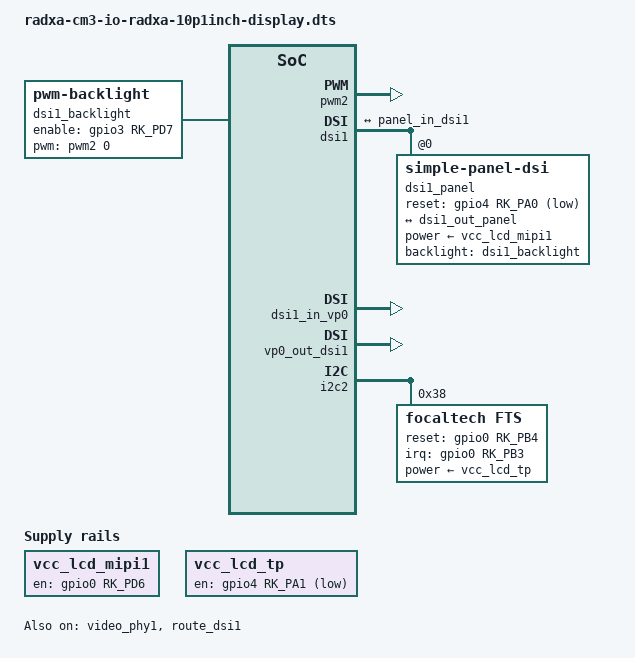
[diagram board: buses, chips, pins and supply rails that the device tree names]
/dts-v1/;
/plugin/;

#include <dt-bindings/gpio/gpio.h>
#include <dt-bindings/pinctrl/rockchip.h>
#include <dt-bindings/interrupt-controller/irq.h>
#include <dt-bindings/display/drm_mipi_dsi.h>

/ {
	metadata {
		title = "Enable Radxa Display 10HD";
		compatible = "radxa,cm3-io";
		category = "display";
		exclusive = "dsi1", "vp0", "video_phy1", "pwm2";
		description = "Enable Radxa Display 10HD.";
	};

	fragment@0 {
		target-path = "/";

		__overlay__ {
			vcc_lcd_mipi1: vcc-lcd-mipi1 {
				status = "okay";
				compatible = "regulator-fixed";
				regulator-name = "vcc_lcd_mipi1";
				pinctrl-names = "default";
				pinctrl-0 = <&vcc_mipi>;
				gpio = <&gpio0 RK_PD6 GPIO_ACTIVE_HIGH>;
				enable-active-high;
				regulator-boot-on;
				regulator-state-mem {
					regulator-off-in-suspend;
				};
			};

			vcc_lcd_tp: vcc-lcd-tp {
				status = "okay";
				compatible = "regulator-fixed";
				regulator-name = "vcc_lcd_tp";
				pinctrl-names = "default";
				pinctrl-0 = <&vcc_tp>;
				gpio = <&gpio4 RK_PA1 GPIO_ACTIVE_LOW>;
				enable-active-low;
				regulator-boot-on;
				regulator-state-mem {
					regulator-off-in-suspend;
				};
			};

			dsi1_backlight: dsi1-backlight {
				status = "okay";
				compatible = "pwm-backlight";
				pwms = <&pwm2 0 25000 0>;
				brightness-levels = <
					255 254 253 252 251 250 249 248
					247 246 245 244 243 242 241 240
					239 238 237 236 235 234 233 232
					231 230 229 228 227 226 225 224
					223 222 221 220 219 218 217 216
					215 214 213 212 211 210 209 208
					207 206 205 204 203 202 201 200
					199 198 197 196 195 194 193 192
					191 190 189 188 187 186 185 184
					183 182 181 180 179 178 177 176
					175 174 173 172 171 170 169 168
					167 166 165 164 163 162 161 160
					159 158 157 156 155 154 153 152
					151 150 149 148 147 146 145 144
					143 142 141 140 139 138 137 136
					135 134 133 132 131 130 129 128
					127 126 125 124 123 122 121 120
					119 118 117 116 115 114 113 112
					111 110 109 108 107 106 105 104
					103 102 101 100  99  98  97  96
					95  94  93  92  91  90  89  88
					87  86  85  84  83  82  81  80
					79  78  77  76  75  74  73  72
					71  70  69  68  67  66  65  64
					63  62  61  60  59  58  57  56
					55  54  53  52  51  50  49  48
					47  46  45  44  43  42  41  40
					39  38  38  37  37  36  36  35
					35  34  34  33  33  32  32  31
					31  30  30  29  29  28  28  27
					27  26  26  25  25  24  24  23
					23  22  22  21  21  20  20   0
				>;
				default-brightness-level = <200>;
				enable-gpios = <&gpio3 RK_PD7 GPIO_ACTIVE_HIGH>;
				pinctrl-names = "default";
				pinctrl-0 = <&dsi1_backlight_en>;
			};
		};
	};

	fragment@2 {
		target = <&pwm2>;

		__overlay__ {
			status = "okay";
		};
	};

	fragment@3 {
		target = <&dsi1>;

		__overlay__ {
			status = "okay";

			dsi1_panel: panel@0 {
					status = "okay";
					compatible = "simple-panel-dsi";
					reg = <0>;
					backlight = <&dsi1_backlight>;

					power-supply = <&vcc_lcd_mipi1>;
					reset-gpios = <&gpio4 RK_PA0 GPIO_ACTIVE_LOW>;
					pinctrl-names = "default";
					pinctrl-0 = <&dsi1_lcd_rst_gpio>;

					prepare-delay-ms = <120>;
					reset-delay-ms = <120>;
					init-delay-ms = <120>;
					stbyb-delay-ms = <120>;
					enable-delay-ms = <100>;
					disable-delay-ms = <120>;
					unprepare-delay-ms = <120>;

					width-mm = <135>;
					height-mm = <216>;

					dsi,flags = <(MIPI_DSI_MODE_VIDEO | MIPI_DSI_MODE_VIDEO_BURST |
						MIPI_DSI_MODE_LPM | MIPI_DSI_MODE_EOT_PACKET)>;
					dsi,format = <MIPI_DSI_FMT_RGB888>;
					dsi,lanes  = <4>;

					panel-init-sequence = [
						15 00 02 E0 00
						15 00 02 E1 93
						15 00 02 E2 65
						15 00 02 E3 F8
						15 00 02 80 03
						15 00 02 E0 01
						15 00 02 00 00
						15 00 02 01 3B
						15 00 02 0C 74
						15 00 02 17 00
						15 00 02 18 AF
						15 00 02 19 00
						15 00 02 1A 00
						15 00 02 1B AF
						15 00 02 1C 00
						15 00 02 35 26
						15 00 02 37 09
						15 00 02 38 04
						15 00 02 39 00
						15 00 02 3A 01
						15 00 02 3C 78
						15 00 02 3D FF
						15 00 02 3E FF
						15 00 02 3F 7F
						15 00 02 40 06
						15 00 02 41 A0
						15 00 02 42 81
						15 00 02 43 14
						15 00 02 44 23
						15 00 02 45 28
						15 00 02 55 02
						15 00 02 57 69
						15 00 02 59 0A
						15 00 02 5A 2A
						15 00 02 5B 17
						15 00 02 5D 7F
						15 00 02 5E 6B
						15 00 02 5F 5C
						15 00 02 60 4F
						15 00 02 61 4D
						15 00 02 62 3F
						15 00 02 63 42
						15 00 02 64 2B
						15 00 02 65 44
						15 00 02 66 43
						15 00 02 67 43
						15 00 02 68 63
						15 00 02 69 52
						15 00 02 6A 5A
						15 00 02 6B 4F
						15 00 02 6C 4E
						15 00 02 6D 20
						15 00 02 6E 0F
						15 00 02 6F 00
						15 00 02 70 7F
						15 00 02 71 6B
						15 00 02 72 5C
						15 00 02 73 4F
						15 00 02 74 4D
						15 00 02 75 3F
						15 00 02 76 42
						15 00 02 77 2B
						15 00 02 78 44
						15 00 02 79 43
						15 00 02 7A 43
						15 00 02 7B 63
						15 00 02 7C 52
						15 00 02 7D 5A
						15 00 02 7E 4F
						15 00 02 7F 4E
						15 00 02 80 20
						15 00 02 81 0F
						15 00 02 82 00
						15 00 02 E0 02
						15 00 02 00 02
						15 00 02 01 02
						15 00 02 02 00
						15 00 02 03 00
						15 00 02 04 1E
						15 00 02 05 1E
						15 00 02 06 1F
						15 00 02 07 1F
						15 00 02 08 1F
						15 00 02 09 17
						15 00 02 0A 17
						15 00 02 0B 37
						15 00 02 0C 37
						15 00 02 0D 47
						15 00 02 0E 47
						15 00 02 0F 45
						15 00 02 10 45
						15 00 02 11 4B
						15 00 02 12 4B
						15 00 02 13 49
						15 00 02 14 49
						15 00 02 15 1F
						15 00 02 16 01
						15 00 02 17 01
						15 00 02 18 00
						15 00 02 19 00
						15 00 02 1A 1E
						15 00 02 1B 1E
						15 00 02 1C 1F
						15 00 02 1D 1F
						15 00 02 1E 1F
						15 00 02 1F 17
						15 00 02 20 17
						15 00 02 21 37
						15 00 02 22 37
						15 00 02 23 46
						15 00 02 24 46
						15 00 02 25 44
						15 00 02 26 44
						15 00 02 27 4A
						15 00 02 28 4A
						15 00 02 29 48
						15 00 02 2A 48
						15 00 02 2B 1F
						15 00 02 2C 01
						15 00 02 2D 01
						15 00 02 2E 00
						15 00 02 2F 00
						15 00 02 30 1F
						15 00 02 31 1F
						15 00 02 32 1E
						15 00 02 33 1E
						15 00 02 34 1F
						15 00 02 35 17
						15 00 02 36 17
						15 00 02 37 37
						15 00 02 38 37
						15 00 02 39 08
						15 00 02 3A 08
						15 00 02 3B 0A
						15 00 02 3C 0A
						15 00 02 3D 04
						15 00 02 3E 04
						15 00 02 3F 06
						15 00 02 40 06
						15 00 02 41 1F
						15 00 02 42 02
						15 00 02 43 02
						15 00 02 44 00
						15 00 02 45 00
						15 00 02 46 1F
						15 00 02 47 1F
						15 00 02 48 1E
						15 00 02 49 1E
						15 00 02 4A 1F
						15 00 02 4B 17
						15 00 02 4C 17
						15 00 02 4D 37
						15 00 02 4E 37
						15 00 02 4F 09
						15 00 02 50 09
						15 00 02 51 0B
						15 00 02 52 0B
						15 00 02 53 05
						15 00 02 54 05
						15 00 02 55 07
						15 00 02 56 07
						15 00 02 57 1F
						15 00 02 58 40
						15 00 02 5B 30
						15 00 02 5C 16
						15 00 02 5D 34
						15 00 02 5E 05
						15 00 02 5F 02
						15 00 02 63 00
						15 00 02 64 6A
						15 00 02 67 73
						15 00 02 68 1D
						15 00 02 69 08
						15 00 02 6A 6A
						15 00 02 6B 08
						15 00 02 6C 00
						15 00 02 6D 00
						15 00 02 6E 00
						15 00 02 6F 88
						15 00 02 75 FF
						15 00 02 77 DD
						15 00 02 78 3F
						15 00 02 79 15
						15 00 02 7A 17
						15 00 02 7D 14
						15 00 02 7E 82
						15 00 02 E0 04
						15 00 02 00 0E
						15 00 02 02 B3
						15 00 02 09 61
						15 00 02 0E 48
						15 00 02 E0 00
						15 00 02 E6 02
						15 00 02 E7 0C
						05 78 01 11
						05 14 01 29
					];

					panel-exit-sequence = [
						05 00 01 28
						05 00 01 10
					];

					display_timings0: display-timings {
						native-mode = <&dsi1_timing>;

						dsi1_timing: timing0 {
							clock-frequency = <70000000>;
							hactive = <800>;
							vactive = <1280>;

							hsync-len = <18>;
							hback-porch = <20>;
							hfront-porch = <40>;

							vsync-len = <4>;
							vback-porch = <20>;
							vfront-porch = <20>;

							hsync-active = <0>;
							vsync-active = <0>;
							de-active = <0>;
							pixelclk-active = <1>;
						};
					};

					ports {
						#address-cells = <1>;
						#size-cells = <0>;

						port@0 {
							reg = <0>;
							panel_in_dsi1: endpoint {
								remote-endpoint = <&dsi1_out_panel>;
							};
						};
					};
				};

				ports {
					#address-cells = <1>;
					#size-cells = <0>;

					port@1 {
						reg = <1>;
						dsi1_out_panel: endpoint {
							remote-endpoint = <&panel_in_dsi1>;
						};
					};
				};
		};
	};

	fragment@4 {
		target = <&video_phy1>;

		__overlay__ {
			status = "okay";
		};
	};

	fragment@5 {
		target = <&dsi1_in_vp0>;

		__overlay__ {
			status = "okay";
		};
	};

	fragment@6 {
		target = <&dsi1_in_vp1>;

		__overlay__ {
			status = "disabled";
		};
	};

	fragment@7 {
		target = <&vp0_out_dsi1>;

		__overlay__ {
			status = "okay";
		};
	};

	fragment@8 {
		target = <&vp1_out_dsi1>;

		__overlay__ {
			status = "disabled";
		};
	};

	fragment@9 {
		target = <&route_dsi1>;

		__overlay__ {
			status = "okay";
			connect = <&vp0_out_dsi1>;
		};
	};

	fragment@10 {
		target = <&i2c2>;

		__overlay__ {
			status = "okay";
			pinctrl-0 = <&i2c2m1_xfer>;

			focaltech: focaltech@38 {
				status = "okay";
				compatible = "focaltech,fts";
				reg = <0x38>;
				power-supply = <&vcc_lcd_tp>;
				pinctrl-names = "default";
				pinctrl-0 = <&touch_gpio>;
				focaltech,reset-gpio = <&gpio0 RK_PB4 GPIO_ACTIVE_HIGH>;
				focaltech,irq-gpio = <&gpio0 RK_PB3 IRQ_TYPE_LEVEL_LOW>;
				focaltech,max-touch-number = <5>;
				focaltech,display-coords = <0 0 800 1280>;
			};
		};
	};

	fragment@11 {
		target = <&hdmi>;

		__overlay__ {
			status = "disabled";
		};
	};

	fragment@12 {
		target = <&hdmi_in_vp0>;

		__overlay__ {
			status = "disabled";
		};
	};

	fragment@13 {
		target = <&hdmi_sound>;

		__overlay__ {
			status = "disabled";
		};
	};

	fragment@14 {
		target = <&route_hdmi>;

		__overlay__ {
			status = "disabled";
		};
	};

	fragment@15 {
		target = <&pinctrl>;

		__overlay__ {
			lcd-vcc {
				vcc_mipi: vcc-mipi {
					rockchip,pins = <0 RK_PD6 RK_FUNC_GPIO &pcfg_pull_up>;
				};

				vcc_tp: vcc-tp {
					rockchip,pins = <4 RK_PA1 RK_FUNC_GPIO &pcfg_pull_down>;
				};
			};

			dsi1-lcd {
				dsi1_lcd_rst_gpio: dsi1-lcd-rst-gpio {
					rockchip,pins = <4 RK_PA0 RK_FUNC_GPIO &pcfg_pull_up>;
				};

				dsi1_backlight_en: dsi1-backlight-en {
					rockchip,pins = <3 RK_PD7 RK_FUNC_GPIO &pcfg_pull_up>;
				};
			};

			touch {
				touch_gpio: touch-gpio {
					rockchip,pins =
						<0 RK_PB4 RK_FUNC_GPIO &pcfg_pull_up>,
						<0 RK_PB3 RK_FUNC_GPIO &pcfg_pull_none>;
				};
			};
		};
	};

};
